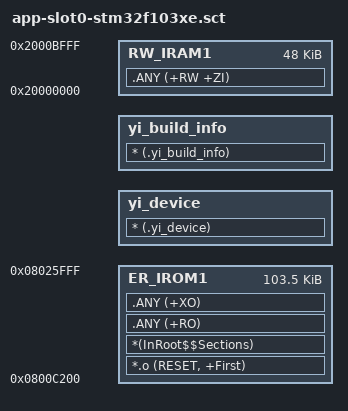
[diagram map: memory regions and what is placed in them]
; Primary slot starts at 0x0800C000. MCUboot reserves a 0x200-byte header,
; so the application's vector table and linked image start at 0x0800C200.
LR_IROM1 0x0800C200 0x00019E00 {
  ER_IROM1 0x0800C200 0x00019E00 {
    *.o (RESET, +First)
    *(InRoot$$Sections)
    .ANY (+RO)
    .ANY (+XO)
  }

  yi_device +0 ALIGN 4 {
    * (.yi_device)
  }

  yi_build_info +0 ALIGN 4 {
    * (.yi_build_info)
  }

  RW_IRAM1 0x20000000 0x0000C000 {
    .ANY (+RW +ZI)
  }
}
